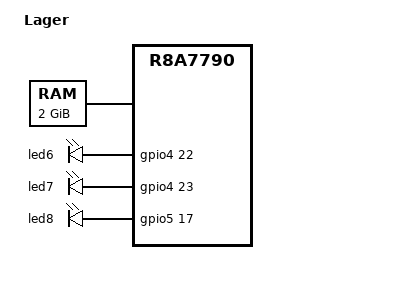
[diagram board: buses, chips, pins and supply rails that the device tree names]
/*
 * Device Tree Source for the Lager board
 *
 * Copyright (C) 2013 Renesas Solutions Corp.
 *
 * This file is licensed under the terms of the GNU General Public License
 * version 2.  This program is licensed "as is" without any warranty of any
 * kind, whether express or implied.
 */

/dts-v1/;
/include/ "r8a7790.dtsi"
#include <dt-bindings/gpio/gpio.h>

/ {
	model = "Lager";
	compatible = "renesas,lager-reference", "renesas,r8a7790";

	chosen {
		bootargs = "console=ttySC6,115200 ignore_loglevel rw";
	};

	memory@40000000 {
		device_type = "memory";
		reg = <0 0x40000000 0 0x80000000>;
	};

	lbsc {
		#address-cells = <1>;
		#size-cells = <1>;
	};

	leds {
		compatible = "gpio-leds";
		led6 {
			gpios = <&gpio4 22 GPIO_ACTIVE_HIGH>;
		};
		led7 {
			gpios = <&gpio4 23 GPIO_ACTIVE_HIGH>;
		};
		led8 {
			gpios = <&gpio5 17 GPIO_ACTIVE_HIGH>;
		};
	};
};
